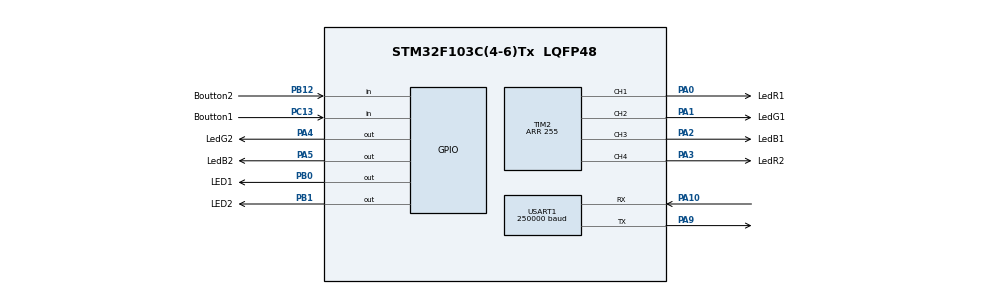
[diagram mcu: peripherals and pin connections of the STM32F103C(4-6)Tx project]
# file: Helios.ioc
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Mcu.Family=STM32F1
Mcu.Name=STM32F103C(4-6)Tx
Mcu.Package=LQFP48
NVIC.PriorityGroup=NVIC_PRIORITYGROUP_4
NVIC.TIM3_IRQn=true\:0\:0\:false\:false\:true\:true\:true\:true
NVIC.USART1_IRQn=true\:0\:0\:false\:false\:true\:true\:true\:true
PA0-WKUP.GPIO_Label=LedR1
PA0-WKUP.Signal=S_TIM2_CH1_ETR
PA1.GPIO_Label=LedG1
PA1.Signal=S_TIM2_CH2
PA10.Mode=Asynchronous
PA10.Signal=USART1_RX
PA13.Signal=SYS_JTMS-SWDIO
PA14.Signal=SYS_JTCK-SWCLK
PA2.GPIO_Label=LedB1
PA2.Signal=S_TIM2_CH3
PA3.GPIO_Label=LedR2
PA3.Signal=S_TIM2_CH4
PA4.GPIO_Label=LedG2
PA4.Signal=GPIO_Output
PA5.GPIO_Label=LedB2
PA5.Signal=GPIO_Output
PA9.Mode=Asynchronous
PA9.Signal=USART1_TX
PB0.GPIO_Label=LED1
PB0.Signal=GPIO_Output
PB1.GPIO_Label=LED2
PB1.Signal=GPIO_Output
PB12.GPIO_Label=Boutton2
PB12.Signal=GPIO_Input
PC13-TAMPER-RTC.GPIO_Label=Boutton1
PC13-TAMPER-RTC.Signal=GPIO_Input
ProjectManager.HeapSize=0x200
ProjectManager.StackSize=0x400
ProjectManager.TargetToolchain=STM32CubeIDE
RCC.APB1Freq_Value=8000000
RCC.APB2Freq_Value=8000000
SH.S_TIM2_CH1_ETR.0=TIM2_CH1,PWM Generation1 CH1
SH.S_TIM2_CH2.0=TIM2_CH2,PWM Generation2 CH2
SH.S_TIM2_CH3.0=TIM2_CH3,PWM Generation3 CH3
SH.S_TIM2_CH4.0=TIM2_CH4,PWM Generation4 CH4
TIM2.Channel-PWM\ Generation1\ CH1=TIM_CHANNEL_1
TIM2.Channel-PWM\ Generation2\ CH2=TIM_CHANNEL_2
TIM2.Channel-PWM\ Generation3\ CH3=TIM_CHANNEL_3
TIM2.Channel-PWM\ Generation4\ CH4=TIM_CHANNEL_4
TIM2.Period=255
TIM3.Period=255
TIM3.Prescaler=71
USART1.BaudRate=250000
USART1.StopBits=STOPBITS_2
USART1.VirtualMode=VM_ASYNC
VP_SYS_VS_ND.Mode=No_Debug
VP_TIM3_VS_ClockSourceINT.Mode=Internal
board=custom

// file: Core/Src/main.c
/* USER CODE BEGIN Header */
/**
  ******************************************************************************
  * @file           : main.c
  * @brief          : Main program body
  ******************************************************************************
  * @attention
  *
  * Copyright (c) 2026 STMicroelectronics.
  * All rights reserved.
  *
  * This software is licensed under terms that can be found in the LICENSE file
  * in the root directory of this software component.
  * If no LICENSE file comes with this software, it is provided AS-IS.
  *
  ******************************************************************************
  */
/* USER CODE END Header */
#include "main.h"
#include "tim.h"
#include "usart.h"
#include "gpio.h"

/* USER CODE BEGIN Includes */
#include "dmx.h"
#include "dmx_parsec.h"
#include "strobe.h"
/* USER CODE END Includes */

void SystemClock_Config(void);

int main(void)
{

  /* MCU Configuration--------------------------------------------------------*/

  /* Reset of all peripherals, Initializes the Flash interface and the Systick. */
  HAL_Init();

  /* Configure the system clock */
  SystemClock_Config();

  /* Initialize all configured peripherals */
  MX_GPIO_Init();
  MX_USART1_UART_Init();
  MX_TIM2_Init();
  MX_TIM3_Init();
  /* USER CODE BEGIN 2 */

  DMX_Init();

  STROBE_Init();

  DMX_StartReception();

  /* USER CODE END 2 */

  /* Infinite loop */
  /* USER CODE BEGIN WHILE */
  while (1)
  {
	  /*
	    if(DMX_NewFrameAvailable())
	    {
			/* TEST LED */
	    	/*
			HAL_GPIO_TogglePin(
					LED1_GPIO_Port,
					LED1_Pin
			);

	        __HAL_TIM_SET_COMPARE(
	            &htim2,
	            TIM_CHANNEL_1,
	            DMX_GetChannel(1)
	        );

	        DMX_ClearFrameFlag();
	    }*/

	  if(DMX_NewFrameAvailable())
	      {
	          DMX_ParseFrame();

	          STROBE_Update(
	              DMX_GetParsedData()
	          );

	          DMX_ClearFrameFlag();
	      }

    /* USER CODE END WHILE */

  }
}

void SystemClock_Config(void)
{
  RCC_OscInitTypeDef RCC_OscInitStruct = {0};
  RCC_ClkInitTypeDef RCC_ClkInitStruct = {0};

  /** Initializes the RCC Oscillators according to the specified parameters
  * in the RCC_OscInitTypeDef structure.
  */
  RCC_OscInitStruct.OscillatorType = RCC_OSCILLATORTYPE_HSI;
  RCC_OscInitStruct.HSIState = RCC_HSI_ON;
  RCC_OscInitStruct.HSICalibrationValue = RCC_HSICALIBRATION_DEFAULT;
  RCC_OscInitStruct.PLL.PLLState = RCC_PLL_NONE;
  if (HAL_RCC_OscConfig(&RCC_OscInitStruct) != HAL_OK)
  {
    Error_Handler();
  }

  /** Initializes the CPU, AHB and APB buses clocks
  */
  RCC_ClkInitStruct.ClockType = RCC_CLOCKTYPE_HCLK|RCC_CLOCKTYPE_SYSCLK
                              |RCC_CLOCKTYPE_PCLK1|RCC_CLOCKTYPE_PCLK2;
  RCC_ClkInitStruct.SYSCLKSource = RCC_SYSCLKSOURCE_HSI;
  RCC_ClkInitStruct.AHBCLKDivider = RCC_SYSCLK_DIV1;
  RCC_ClkInitStruct.APB1CLKDivider = RCC_HCLK_DIV1;
  RCC_ClkInitStruct.APB2CLKDivider = RCC_HCLK_DIV1;

  if (HAL_RCC_ClockConfig(&RCC_ClkInitStruct, FLASH_LATENCY_0) != HAL_OK)
  {
    Error_Handler();
  }
}

void Error_Handler(void)
{
  __disable_irq();
  while (1)
  {
  }
}
